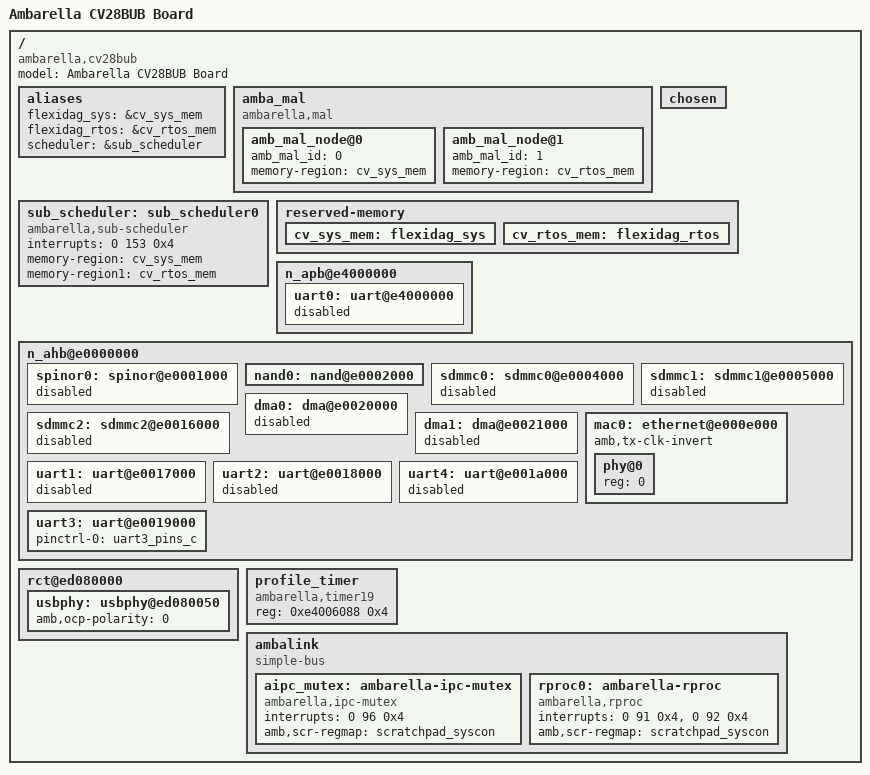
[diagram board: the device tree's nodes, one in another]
/*
 * Copyright (C) 2013 Ambarella,Inc. - http://www.ambarella.com/
 * Author: Cao Rongrong <rrcao@ambarella.com>
 *
 * This program is free software; you can redistribute it and/or modify
 * it under the terms of the GNU General Public License version 2 as
 * published by the Free Software Foundation.
 */
/dts-v1/;

/include/ "ambarella-cv28-ambalink.dtsi"

/ {
	model = "Ambarella CV28BUB Board";
	compatible = "ambarella,cv28bub", "ambarella,cv28";

	aliases {
		flexidag_sys = &cv_sys_mem;
		flexidag_rtos = &cv_rtos_mem;
		scheduler = &sub_scheduler;
	};

	amba_mal {
		compatible = "ambarella,mal";
		amb_mal_node@0 {
			amb_mal_id = <0>;
			memory-region = <&cv_sys_mem>;
		};

		amb_mal_node@1 {
			amb_mal_id = <1>;
			memory-region = <&cv_rtos_mem>;
		};
	};

	chosen {
	};

	sub_scheduler: sub_scheduler0 {
		compatible = "ambarella,sub-scheduler";
		interrupts = <0 153 0x4>;
		memory-region = <&cv_sys_mem>;
		memory-region1 = <&cv_rtos_mem>;
	};

	reserved-memory {
		device_type = "reserved-memory";
		cv_sys_mem: flexidag_sys {
		};
		cv_rtos_mem: flexidag_rtos {
		};
	};

	n_apb@e4000000 {
		uart0: uart@e4000000 {
			status = "disabled";
		};
	};

	n_ahb@e0000000 {
		spinor0: spinor@e0001000 {
			status = "disabled";
		};
		nand0: nand@e0002000 {
			status = "ok";
		};
		sdmmc0: sdmmc0@e0004000 {
			/*pwr-gpios = <&gpio 81 0x1>; */
			/*v18-gpios = <&gpio 105 0x1>;*/
			status = "disabled";
		};

		sdmmc1: sdmmc1@e0005000 {
			/*pwr-gpios = <&gpio 80 0x1>; */
			/*v18-gpios = <&gpio 0 0x1>;*/
			status = "disabled";
		};

		sdmmc2: sdmmc2@e0016000 {
			status = "disabled";
		};

		dma0: dma@e0020000 {
			/* amb,dma-startchannel = <2>; */ /* Prevent conflict between RTOS. */
			status = "disabled";
		};

		dma1: dma@e0021000 {
			/* amb,dma-startchannel = <2>; */ /* Prevent conflict between RTOS. */
			status = "disabled";
		};

		mac0: ethernet@e000e000 {
			amb,tx-clk-invert;
			phy@0 {
				reg = <0>;
			};
		};

		uart1: uart@e0017000 {
			/*/delete-property/ amb,msr-used;    */
			/delete-property/ amb,txdma-used;
			/delete-property/ amb,rxdma-used;
			/delete-property/ pinctrl-0;
			status = "disabled";
		};
		uart2: uart@e0018000 {
			/*/delete-property/ amb,msr-used;    */
			/delete-property/ amb,txdma-used;
			/delete-property/ amb,rxdma-used;
			/delete-property/ pinctrl-0;
			status = "disabled";
		};

		uart3: uart@e0019000 {
			/*/delete-property/ amb,msr-used;    */
			pinctrl-0 = <&uart3_pins_c>;
			status = "ok";
		};

		uart4: uart@e001a000 {
			/*/delete-property/ amb,msr-used;    */
			/delete-property/ amb,txdma-used;
			/delete-property/ amb,rxdma-used;
			/delete-property/ pinctrl-0;
			status = "disabled";
		};
	};

	/*
	secure-monitor {
		device = <&s_scratchpad &rct_syscon>;
		device = <&rct_syscon>;
	};
	*/

	rct@ed080000 {
		usbphy: usbphy@ed080050 {
			/* high will trigger the ocp interrupt */
			amb,ocp-polarity = <0>;
			/*pinctrl-names = "default";
			/*pinctrl-0 = <&usb_host0_pins_b>;*/
			/*status = "disabled";*/
		};
	};

	/* for profiling, see aipc_profile.c */
	profile_timer {
		compatible = "ambarella,timer19";
		reg = <0xe4006088 0x4>;
	};

	ambalink {
		compatible = "simple-bus";
		#address-cells = <1>;
		#size-cells = <1>;

		aipc_mutex: ambarella-ipc-mutex {
			compatible = "ambarella,ipc-mutex";
			interrupts = <0 96 0x4>;
			amb,scr-regmap = <&scratchpad_syscon>;
		};

		/* must be consistent with ambalink_cfg.h */
		rproc0: ambarella-rproc {
			compatible = "ambarella,rproc";
			interrupts = <0 91 0x4>,	/* rvq_rx_irq, get rvq kick from rtos */
				     <0 92 0x4>;	/* svq_rx_irq, get svq ack from rtos */
			amb,scr-regmap = <&scratchpad_syscon>;
		};
	};

};
